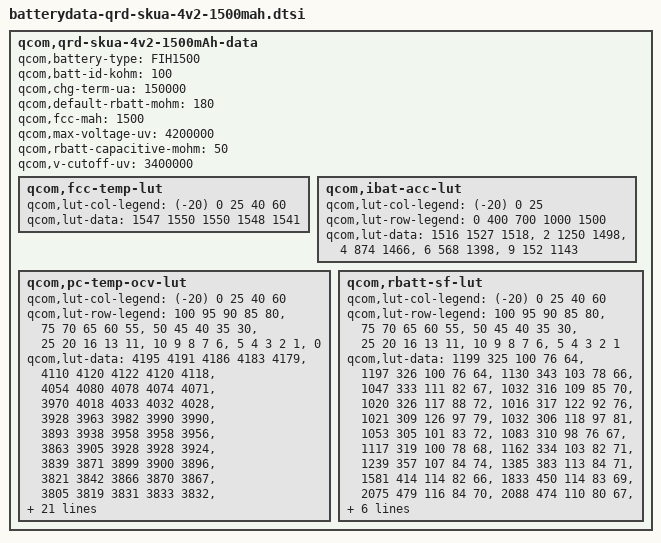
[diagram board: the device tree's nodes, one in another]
/* Copyright (c) 2014, 2020, The Linux Foundation. All rights reserved.
 *
 * This program is free software; you can redistribute it and/or modify
 * it under the terms of the GNU General Public License version 2 and
 * only version 2 as published by the Free Software Foundation.
 *
 * This program is distributed in the hope that it will be useful,
 * but WITHOUT ANY WARRANTY; without even the implied warranty of
 * MERCHANTABILITY or FITNESS FOR A PARTICULAR PURPOSE.  See the
 * GNU General Public License for more details.
 */

qcom,qrd-skua-4v2-1500mAh-data {
	qcom,battery-type = "FIH1500";
	qcom,batt-id-kohm = <100>;
	qcom,chg-term-ua = <150000>;
	qcom,default-rbatt-mohm = <180>;
	qcom,fcc-mah = <1500>;
	qcom,max-voltage-uv = <4200000>;
	qcom,rbatt-capacitive-mohm = <50>;
	qcom,v-cutoff-uv = <3400000>;

	qcom,fcc-temp-lut {
		qcom,lut-col-legend = <(-20) 0 25 40 60>;
		qcom,lut-data = <1547 1550 1550 1548 1541>;
	};

	qcom,ibat-acc-lut {
		qcom,lut-col-legend = <(-20) 0 25>;
		qcom,lut-row-legend = <0 400 700 1000 1500>;
		qcom,lut-data = <1516 1527 1518>,
				<2 1250 1498>,
				<4 874 1466>,
				<6 568 1398>,
				<9 152 1143>;
	};

	qcom,pc-temp-ocv-lut {
		qcom,lut-col-legend = <(-20) 0 25 40 60>;
		qcom,lut-row-legend = <100 95 90 85 80>,
					<75 70 65 60 55>,
					<50 45 40 35 30>,
					<25 20 16 13 11>,
					<10 9 8 7 6>,
					<5 4 3 2 1>,
					<0>;
		qcom,lut-data = <4195 4191 4186 4183 4179>,
				<4110 4120 4122 4120 4118>,
				<4054 4080 4078 4074 4071>,
				<3970 4018 4033 4032 4028>,
				<3928 3963 3982 3990 3990>,
				<3893 3938 3958 3958 3956>,
				<3863 3905 3928 3928 3924>,
				<3839 3871 3899 3900 3896>,
				<3821 3842 3866 3870 3867>,
				<3805 3819 3831 3833 3832>,
				<3791 3802 3808 3808 3808>,
				<3778 3791 3793 3793 3792>,
				<3766 3782 3782 3782 3780>,
				<3756 3775 3775 3772 3770>,
				<3744 3768 3769 3762 3755>,
				<3732 3758 3758 3748 3734>,
				<3717 3741 3740 3730 3716>,
				<3702 3722 3718 3709 3695>,
				<3690 3706 3696 3687 3673>,
				<3678 3696 3689 3682 3670>,
				<3670 3693 3688 3681 3669>,
				<3660 3690 3687 3680 3668>,
				<3650 3686 3685 3678 3666>,
				<3636 3682 3682 3675 3663>,
				<3616 3672 3672 3662 3648>,
				<3588 3648 3643 3631 3612>,
				<3549 3602 3596 3583 3565>,
				<3491 3538 3532 3521 3500>,
				<3398 3448 3448 3437 3414>,
				<3225 3308 3315 3304 3274>,
				<3000 3000 3000 3000 3000>;
	};

	qcom,rbatt-sf-lut {
		qcom,lut-col-legend = <(-20) 0 25 40 60>;
		qcom,lut-row-legend = <100 95 90 85 80>,
					<75 70 65 60 55>,
					<50 45 40 35 30>,
					<25 20 16 13 11>,
					<10 9 8 7 6>,
					<5 4 3 2 1>;
		qcom,lut-data = <1199 325 100 76 64>,
				<1197 326 100 76 64>,
				<1130 343 103 78 66>,
				<1047 333 111 82 67>,
				<1032 316 109 85 70>,
				<1020 326 117 88 72>,
				<1016 317 122 92 76>,
				<1021 309 126 97 79>,
				<1032 306 118 97 81>,
				<1053 305 101 83 72>,
				<1083 310 98 76 67>,
				<1117 319 100 78 68>,
				<1162 334 103 82 71>,
				<1239 357 107 84 74>,
				<1385 383 113 84 71>,
				<1581 414 114 82 66>,
				<1833 450 114 83 69>,
				<2075 479 116 84 70>,
				<2088 474 110 80 67>,
				<2211 498 110 80 67>,
				<2381 519 114 82 69>,
				<2572 544 119 86 71>,
				<2803 574 124 89 73>,
				<3096 610 131 93 74>,
				<3460 647 134 91 72>,
				<3944 675 132 88 69>,
				<4631 717 135 90 73>,
				<5682 784 144 95 77>,
				<7524 947 161 104 84>,
				<15049 1427 197 130 168>;
	};
};

